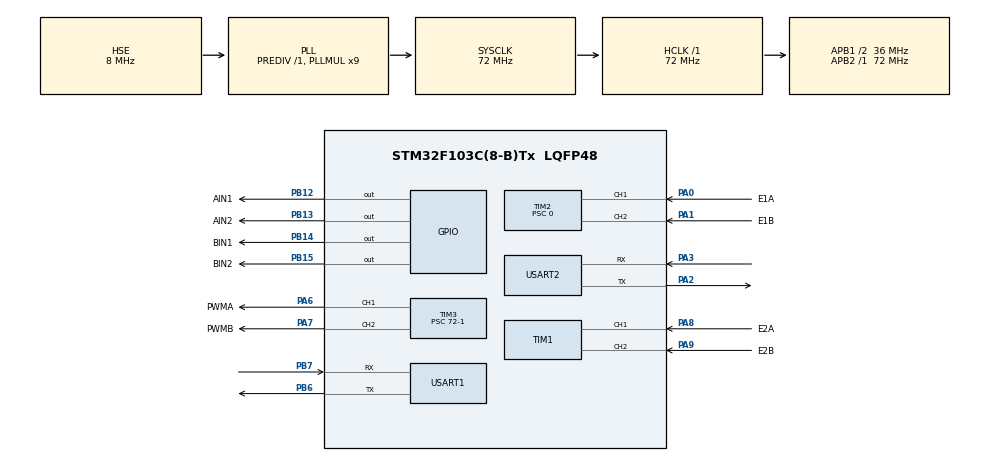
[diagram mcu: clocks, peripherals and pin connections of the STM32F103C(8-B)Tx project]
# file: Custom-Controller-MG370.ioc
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Dma.Request0=USART2_RX
Dma.Request1=USART2_TX
Dma.Request2=USART1_RX
Dma.Request3=USART1_TX
Dma.USART1_RX.2.Direction=DMA_PERIPH_TO_MEMORY
Dma.USART1_RX.2.Instance=DMA1_Channel5
Dma.USART1_RX.2.MemDataAlignment=DMA_MDATAALIGN_BYTE
Dma.USART1_RX.2.MemInc=DMA_MINC_ENABLE
Dma.USART1_RX.2.Mode=DMA_NORMAL
Dma.USART1_RX.2.PeriphDataAlignment=DMA_PDATAALIGN_BYTE
Dma.USART1_RX.2.PeriphInc=DMA_PINC_DISABLE
Dma.USART1_RX.2.Priority=DMA_PRIORITY_LOW
Dma.USART1_TX.3.Direction=DMA_MEMORY_TO_PERIPH
Dma.USART1_TX.3.Instance=DMA1_Channel4
Dma.USART1_TX.3.MemDataAlignment=DMA_MDATAALIGN_BYTE
Dma.USART1_TX.3.MemInc=DMA_MINC_ENABLE
Dma.USART1_TX.3.Mode=DMA_NORMAL
Dma.USART1_TX.3.PeriphDataAlignment=DMA_PDATAALIGN_BYTE
Dma.USART1_TX.3.PeriphInc=DMA_PINC_DISABLE
Dma.USART1_TX.3.Priority=DMA_PRIORITY_LOW
Dma.USART2_RX.0.Direction=DMA_PERIPH_TO_MEMORY
Dma.USART2_RX.0.Instance=DMA1_Channel6
Dma.USART2_RX.0.MemDataAlignment=DMA_MDATAALIGN_BYTE
Dma.USART2_RX.0.MemInc=DMA_MINC_ENABLE
Dma.USART2_RX.0.Mode=DMA_NORMAL
Dma.USART2_RX.0.PeriphDataAlignment=DMA_PDATAALIGN_BYTE
Dma.USART2_RX.0.PeriphInc=DMA_PINC_DISABLE
Dma.USART2_RX.0.Priority=DMA_PRIORITY_LOW
Dma.USART2_TX.1.Direction=DMA_MEMORY_TO_PERIPH
Dma.USART2_TX.1.Instance=DMA1_Channel7
Dma.USART2_TX.1.MemDataAlignment=DMA_MDATAALIGN_BYTE
Dma.USART2_TX.1.MemInc=DMA_MINC_ENABLE
Dma.USART2_TX.1.Mode=DMA_NORMAL
Dma.USART2_TX.1.PeriphDataAlignment=DMA_PDATAALIGN_BYTE
Dma.USART2_TX.1.PeriphInc=DMA_PINC_DISABLE
Dma.USART2_TX.1.Priority=DMA_PRIORITY_LOW
FREERTOS.Tasks01=CommsTask,40,128,StartCommsTask,As weak,NULL,Dynamic,NULL,NULL;MotorControll,8,128,StartMotorControll,As external,NULL,Dynamic,NULL,NULL
Mcu.Family=STM32F1
Mcu.Name=STM32F103C(8-B)Tx
Mcu.Package=LQFP48
NVIC.DMA1_Channel4_IRQn=true\:5\:0\:false\:false\:true\:true\:false\:true\:true
NVIC.DMA1_Channel5_IRQn=true\:5\:0\:false\:false\:true\:true\:false\:true\:true
NVIC.DMA1_Channel6_IRQn=true\:5\:0\:false\:false\:true\:true\:false\:true\:true
NVIC.DMA1_Channel7_IRQn=true\:5\:0\:false\:false\:true\:true\:false\:true\:true
NVIC.PriorityGroup=NVIC_PRIORITYGROUP_4
NVIC.TIM1_BRK_IRQn=true\:5\:0\:false\:false\:true\:true\:true\:true\:true
NVIC.TIM1_CC_IRQn=true\:5\:0\:false\:false\:true\:true\:true\:true\:true
NVIC.TIM2_IRQn=true\:5\:0\:false\:false\:true\:true\:true\:true\:true
NVIC.TIM4_IRQn=true\:15\:0\:false\:false\:true\:false\:false\:true\:true
NVIC.TimeBase=TIM4_IRQn
NVIC.TimeBaseIP=TIM4
NVIC.USART1_IRQn=true\:5\:0\:false\:false\:true\:true\:true\:true\:true
NVIC.USART2_IRQn=true\:5\:0\:false\:false\:true\:true\:true\:true\:true
PA0-WKUP.GPIO_Label=E1A
PA0-WKUP.Signal=S_TIM2_CH1_ETR
PA1.GPIO_Label=E1B
PA1.Signal=S_TIM2_CH2
PA13.Mode=Serial_Wire
PA13.Signal=SYS_JTMS-SWDIO
PA14.Mode=Serial_Wire
PA14.Signal=SYS_JTCK-SWCLK
PA2.Mode=Asynchronous
PA2.Signal=USART2_TX
PA3.Mode=Asynchronous
PA3.Signal=USART2_RX
PA6.GPIO_Label=PWMA
PA6.Signal=S_TIM3_CH1
PA7.GPIO_Label=PWMB
PA7.Signal=S_TIM3_CH2
PA8.GPIO_Label=E2A
PA8.Signal=S_TIM1_CH1
PA9.GPIO_Label=E2B
PA9.Signal=S_TIM1_CH2
PB12.GPIO_Label=AIN1
PB12.Signal=GPIO_Output
PB13.GPIO_Label=AIN2
PB13.Signal=GPIO_Output
PB14.GPIO_Label=BIN1
PB14.Signal=GPIO_Output
PB15.GPIO_Label=BIN2
PB15.Signal=GPIO_Output
PB6.Mode=Asynchronous
PB6.Signal=USART1_TX
PB7.Mode=Asynchronous
PB7.Signal=USART1_RX
PD0-OSC_IN.Mode=HSE-External-Oscillator
PD0-OSC_IN.Signal=RCC_OSC_IN
PD1-OSC_OUT.Mode=HSE-External-Oscillator
PD1-OSC_OUT.Signal=RCC_OSC_OUT
ProjectManager.HeapSize=0x200
ProjectManager.StackSize=0x400
ProjectManager.TargetToolchain=STM32CubeIDE
RCC.AHBFreq_Value=72000000
RCC.APB1CLKDivider=RCC_HCLK_DIV2
RCC.APB1Freq_Value=36000000
RCC.APB1TimFreq_Value=72000000
RCC.APB2Freq_Value=72000000
RCC.APB2TimFreq_Value=72000000
RCC.HCLKFreq_Value=72000000
RCC.PLLMUL=RCC_PLL_MUL9
RCC.PLLSourceVirtual=RCC_PLLSOURCE_HSE
RCC.SYSCLKFreq_VALUE=72000000
RCC.SYSCLKSource=RCC_SYSCLKSOURCE_PLLCLK
RCC.USBFreq_Value=72000000
SH.S_TIM1_CH1.0=TIM1_CH1,Encoder_Interface
SH.S_TIM1_CH2.0=TIM1_CH2,Encoder_Interface
SH.S_TIM2_CH1_ETR.0=TIM2_CH1,Encoder_Interface
SH.S_TIM2_CH2.0=TIM2_CH2,Encoder_Interface
SH.S_TIM3_CH1.0=TIM3_CH1,PWM Generation1 CH1
SH.S_TIM3_CH2.0=TIM3_CH2,PWM Generation2 CH2
TIM1.EncoderMode=TIM_ENCODERMODE_TI12
TIM2.EncoderMode=TIM_ENCODERMODE_TI12
TIM2.Prescaler=0
TIM3.Channel-PWM\ Generation1\ CH1=TIM_CHANNEL_1
TIM3.Channel-PWM\ Generation2\ CH2=TIM_CHANNEL_2
TIM3.Period=100-1
TIM3.Prescaler=72-1
USART1.VirtualMode=VM_ASYNC
USART2.VirtualMode=VM_ASYNC
VP_CRC_VS_CRC.Mode=CRC_Activate
VP_FREERTOS_VS_CMSIS_V2.Mode=CMSIS_V2
VP_SYS_VS_tim4.Mode=TIM4
VP_TIM3_VS_ClockSourceINT.Mode=Internal
board=custom

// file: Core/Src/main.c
/* USER CODE BEGIN Header */
/**
  ******************************************************************************
  * @file           : main.c
  * @brief          : Main program body
  ******************************************************************************
  * @attention
  *
  * Copyright (c) 2026 STMicroelectronics.
  * All rights reserved.
  *
  * This software is licensed under terms that can be found in the LICENSE file
  * in the root directory of this software component.
  * If no LICENSE file comes with this software, it is provided AS-IS.
  *
  ******************************************************************************
  */
/* USER CODE END Header */
#include "main.h"
#include "cmsis_os.h"
#include "crc.h"
#include "dma.h"
#include "tim.h"
#include "usart.h"
#include "gpio.h"

/* USER CODE BEGIN Includes */
#include "UARTComms.h"
/* USER CODE END Includes */

void SystemClock_Config(void);
void MX_FREERTOS_Init(void);

int main(void)
{

  /* MCU Configuration--------------------------------------------------------*/

  /* Reset of all peripherals, Initializes the Flash interface and the Systick. */
  HAL_Init();

  /* Configure the system clock */
  SystemClock_Config();

  /* Initialize all configured peripherals */
  MX_GPIO_Init();
  MX_DMA_Init();
  MX_TIM3_Init();
  MX_USART2_UART_Init();
  MX_CRC_Init();
  MX_TIM1_Init();
  MX_TIM2_Init();
  MX_USART1_UART_Init();

  /* Init scheduler */
  osKernelInitialize();  /* Call init function for freertos objects (in cmsis_os2.c) */
  MX_FREERTOS_Init();

  /* Start scheduler */
  osKernelStart();

  /* We should never get here as control is now taken by the scheduler */

  /* Infinite loop */
  while (1)
  {

  }
}

void SystemClock_Config(void)
{
  RCC_OscInitTypeDef RCC_OscInitStruct = {0};
  RCC_ClkInitTypeDef RCC_ClkInitStruct = {0};

  /** Initializes the RCC Oscillators according to the specified parameters
  * in the RCC_OscInitTypeDef structure.
  */
  RCC_OscInitStruct.OscillatorType = RCC_OSCILLATORTYPE_HSE;
  RCC_OscInitStruct.HSEState = RCC_HSE_ON;
  RCC_OscInitStruct.HSEPredivValue = RCC_HSE_PREDIV_DIV1;
  RCC_OscInitStruct.HSIState = RCC_HSI_ON;
  RCC_OscInitStruct.PLL.PLLState = RCC_PLL_ON;
  RCC_OscInitStruct.PLL.PLLSource = RCC_PLLSOURCE_HSE;
  RCC_OscInitStruct.PLL.PLLMUL = RCC_PLL_MUL9;
  if (HAL_RCC_OscConfig(&RCC_OscInitStruct) != HAL_OK)
  {
    Error_Handler();
  }

  /** Initializes the CPU, AHB and APB buses clocks
  */
  RCC_ClkInitStruct.ClockType = RCC_CLOCKTYPE_HCLK|RCC_CLOCKTYPE_SYSCLK
                              |RCC_CLOCKTYPE_PCLK1|RCC_CLOCKTYPE_PCLK2;
  RCC_ClkInitStruct.SYSCLKSource = RCC_SYSCLKSOURCE_PLLCLK;
  RCC_ClkInitStruct.AHBCLKDivider = RCC_SYSCLK_DIV1;
  RCC_ClkInitStruct.APB1CLKDivider = RCC_HCLK_DIV2;
  RCC_ClkInitStruct.APB2CLKDivider = RCC_HCLK_DIV1;

  if (HAL_RCC_ClockConfig(&RCC_ClkInitStruct, FLASH_LATENCY_2) != HAL_OK)
  {
    Error_Handler();
  }
}

void HAL_TIM_PeriodElapsedCallback(TIM_HandleTypeDef *htim)
{
  if (htim->Instance == TIM4)
  {
    HAL_IncTick();
  }
}

void Error_Handler(void)
{
  __disable_irq();
  while (1)
  {
  }
}

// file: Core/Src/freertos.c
/* USER CODE BEGIN Header */
/**
  ******************************************************************************
  * File Name          : freertos.c
  * Description        : Code for freertos applications
  ******************************************************************************
  * @attention
  *
  * Copyright (c) 2026 STMicroelectronics.
  * All rights reserved.
  *
  * This software is licensed under terms that can be found in the LICENSE file
  * in the root directory of this software component.
  * If no LICENSE file comes with this software, it is provided AS-IS.
  *
  ******************************************************************************
  */
/* USER CODE END Header */

#include "FreeRTOS.h"
#include "task.h"
#include "main.h"
#include "cmsis_os.h"

/* Definitions for CommsTask */
osThreadId_t CommsTaskHandle;
const osThreadAttr_t CommsTask_attributes = {
  .name = "CommsTask",
  .stack_size = 128 * 4,
  .priority = (osPriority_t) osPriorityHigh,
};
/* Definitions for MotorControll */
osThreadId_t MotorControllHandle;
const osThreadAttr_t MotorControll_attributes = {
  .name = "MotorControll",
  .stack_size = 128 * 4,
  .priority = (osPriority_t) osPriorityLow,
};
/* Definitions for MG370Data */
osMessageQueueId_t MG370DataHandle;
const osMessageQueueAttr_t MG370Data_attributes = {
  .name = "MG370Data"
};

void StartCommsTask(void *argument);
extern void StartMotorControll(void *argument);

void MX_FREERTOS_Init(void); /* (MISRA C 2004 rule 8.1) */

void MX_FREERTOS_Init(void) {

  /* Create the queue(s) */
  /* creation of MG370Data */
  MG370DataHandle = osMessageQueueNew (16, sizeof(uint32_t), &MG370Data_attributes);

  /* Create the thread(s) */
  /* creation of CommsTask */
  CommsTaskHandle = osThreadNew(StartCommsTask, NULL, &CommsTask_attributes);

  /* creation of MotorControll */
  MotorControllHandle = osThreadNew(StartMotorControll, NULL, &MotorControll_attributes);

}

__weak void StartCommsTask(void *argument)
{
  for(;;)
  {
    osDelay(1);
  }
}
